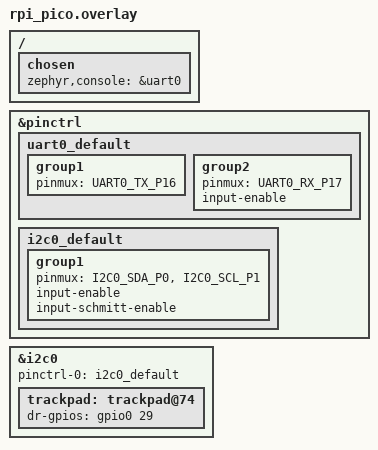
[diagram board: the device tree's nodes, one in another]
/ {
	chosen {
		zephyr,console = &uart0;
	};

};


&pinctrl {
	uart0_default: uart0_default {
		group1 {
			pinmux = <UART0_TX_P16>;
		};
		group2 {
			pinmux = <UART0_RX_P17>;
			input-enable;
		};
	};
	i2c0_default: i2c0_default {
		group1 {
			pinmux = <I2C0_SDA_P0>, <I2C0_SCL_P1>;
			input-enable;
			input-schmitt-enable;
		};
	};
};

&i2c0 {
	pinctrl-0 = <&i2c0_default>;
	status = "okay";
	trackpad: trackpad@74 {
        dr-gpios = <&gpio0 29 (GPIO_ACTIVE_HIGH | GPIO_PULL_DOWN)>;
	};
};
